# R7FA4W1AD register map
Vendor: Renesas; Series: RA4; File version: 1.0
CPU: CM4 r0p1, little endian, MPU, FPU, VTOR, 4 interrupt priority bits
Registers are 8-bit, read-write, reset 0x0 unless marked. A register's access mark holds for its fields unless they carry their own. Offsets are from the block's base; [hi:lo] are bit positions; {n}, {i} and the like mark numbered series.

## DAC12 — 12-bit D/A converter
Base 0x4005E000
0x00 DADR0 16-bit — D/A Data Register 0
  [15:0] DADR — D/A Data RegisterNOTE: When DADPR.DPSEL = 0, the high-order 4 bits are fixed to 0: right justified format. When DADPR.DPSEL = 1, the low-order 4 bits are fixed to 0: left justified format.
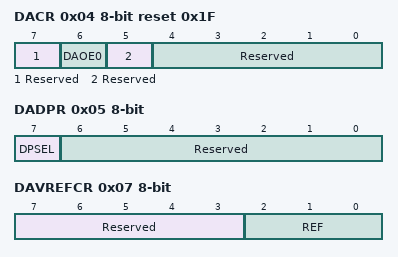
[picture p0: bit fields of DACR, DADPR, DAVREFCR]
0x04 DACR reset 0x1F — D/A Control Register
  [7] Reserved — This bit is read as 0. The write value should be 0.
  [6] DAOE0 — D/A Output Enable 0
    0=Analog output of channel 0 (DA0) is disabled; 1=D/A conversion of channel 0 is enabled. Analog output of channel 0 (DA0) is enabled.
  [5] Reserved — This bit is read as 0. The write value should be 0.
  [4:0] Reserved — These bits are read as 11111. The write value should be 11111.
0x05 DADPR — DADR0 Format Select Register
  [7] DPSEL — DADRm Format Select
    0=Right justified format; 1=Left justified format
  [6:0] Reserved — These bits are read as 0000000. The write value should be 0000000.
0x06 DAADSCR — D/A-A/D Synchronous Start Control Register
  [7] DAADST — D/A-A/D Synchronous Conversion
    0=D/A converter operation does not synchronize with A/D converter operation (unit 1) (countermeasure against interference between D/A and A/D conversions is disabled); 1=D/A converter operation synchronizes with A/D converter operation (unit 1) (countermeasure against interference between D/A and A/D conversions is enabled)
0x07 DAVREFCR — D/A VREF Control Register
  [7:3] Reserved — These bits are read as 00000. The write value should be 00000.
  [2:0] REF — D/A Reference Voltage Select
    0=Not selected; 1=AVCC0/AVSS0; 3=Internal reference voltage/AVSS0; 6=VREFH/VREFL; other=others (Setting prohibited)

## TSN — Temperature Sensor
Base 0x407EC000
0x228 TSCDRH ro reset not defined — Temperature Sensor Calibration Data Register H
  [7:0] TSCDRH — The calibration data stores the higher 8 bits of the convertedvalue.
0x229 TSCDRL ro reset not defined — Temperature Sensor Calibration Data Register L
  [7:0] TSCDRL — The calibration data stores the lower 8 bits of the convertedvalue.

## DTC — Data Transfer Controller
Base 0x40005400
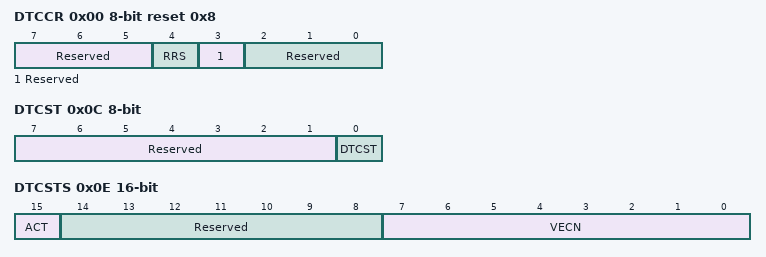
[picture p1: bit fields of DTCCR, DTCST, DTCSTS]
0x00 DTCCR reset 0x8 — DTC Control Register
  [7:5] Reserved — These bits are read as 000. The write value should be 000.
  [4] RRS — DTC Transfer Information Read Skip Enable.
    0=Do not skip transfer information read; 1=Skip transfer information read when vector numbers match
  [3] Reserved — This bit is read as 1. The write value should be 1.
  [2:0] Reserved — These bits are read as 000. The write value should be 000.
0x04 DTCVBR 32-bit — DTC Vector Base Register
  [31:0] DTCVBR — DTC Vector Base Address.Note: A value cannot be set in the lower-order 10 bits. These bits are fixed to 0.
0x0C DTCST — DTC Module Start Register
  [7:1] Reserved — These bits are read as 0000000. The write value should be 0000000.
  [0] DTCST — DTC Module Start
    0=DTC module stop; 1=DTC module start
0x0E DTCSTS 16-bit ro — DTC Status Register
  [15] ACT — DTC Active Flag
    0=DTC transfer operation is not in progress; 1=DTC transfer operation is in progress
  [14:8] Reserved — These bits are read as 0000000.
  [7:0] VECN — DTC-Activating Vector Number MonitoringThese bits indicate the vector number for the activating source when DTC transfer is in progress.The value is only valid if DTC transfer is in progress (the value of the ACT flag is 1)

## KINT — Key Interrupt Function
Base 0x40080000
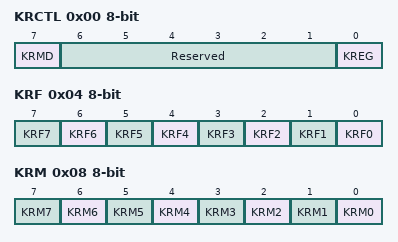
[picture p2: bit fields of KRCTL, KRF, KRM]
0x00 KRCTL — KEY Return Control Register
  [7] KRMD — Usage of Key Interrupt Flags(KR0 to KR7)
    0=Do not use key interrupt flags; 1=Use key interrupt flags
  [6:1] Reserved — These bits are read as 000000. The write value should be 000000.
  [0] KREG — Detection Edge Selection (KRF0 to KRF7)
    0=Falling edge; 1=Rising edge
0x04 KRF write-0-clears read-modifies — KEY Return Flag Register
  [all] fields
    0=No interrupt detected; 1=Interrupt detected
  [n] KRF{n} write-0-clears read-modifies (n=0..7) — Key interrupt flag {n}
0x08 KRM — KEY Return Mode Register
  [all] fields
    0=Does not detect key interrupt signal; 1=Detect key interrupt signal
  [n] KRM{n} (n=0..7) — Key interrupt mode control {n}
